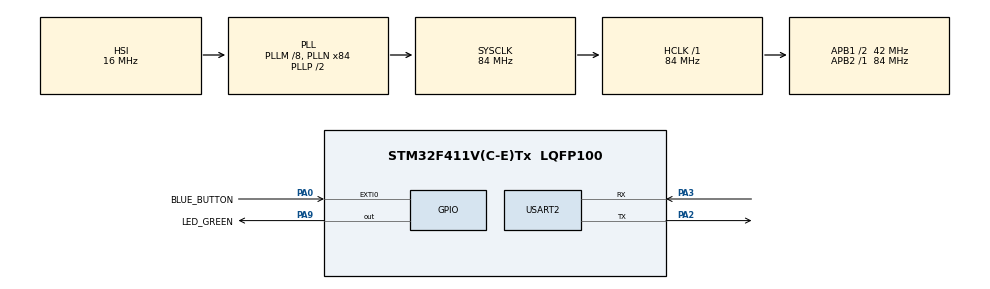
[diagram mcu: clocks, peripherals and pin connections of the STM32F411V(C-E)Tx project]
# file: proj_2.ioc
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FREERTOS.Queues01=adcQueue01,16,uint16_t,0,Dynamic,NULL,NULL
FREERTOS.Tasks01=ConsumerTask,24,256,StartConsumerTask,Default,NULL,Dynamic,NULL,NULL;ProducerTask,8,256,StartProducerTask,Default,NULL,Dynamic,NULL,NULL
FREERTOS.configUSE_NEWLIB_REENTRANT=1
Mcu.Family=STM32F4
Mcu.Name=STM32F411V(C-E)Tx
Mcu.Package=LQFP100
NVIC.EXTI0_IRQn=true\:5\:0\:false\:false\:true\:true\:true\:true\:true
NVIC.PriorityGroup=NVIC_PRIORITYGROUP_4
NVIC.TIM5_IRQn=true\:15\:0\:false\:false\:true\:false\:false\:true\:true
NVIC.TimeBase=TIM5_IRQn
NVIC.TimeBaseIP=TIM5
PA0-WKUP.GPIO_Label=BLUE_BUTTON
PA0-WKUP.Signal=GPXTI0
PA13.Mode=Trace_Asynchronous_SW
PA13.Signal=SYS_JTMS-SWDIO
PA14.Mode=Trace_Asynchronous_SW
PA14.Signal=SYS_JTCK-SWCLK
PA2.Mode=Asynchronous
PA2.Signal=USART2_TX
PA3.Mode=Asynchronous
PA3.Signal=USART2_RX
PA9.GPIO_Label=LED_GREEN
PA9.Signal=GPIO_Output
PB3.Mode=Trace_Asynchronous_SW
PB3.Signal=SYS_JTDO-SWO
ProjectManager.HeapSize=0x200
ProjectManager.StackSize=0x400
ProjectManager.TargetToolchain=STM32CubeIDE
RCC.48MHZClocksFreq_Value=42000000
RCC.AHBFreq_Value=84000000
RCC.APB1CLKDivider=RCC_HCLK_DIV2
RCC.APB1Freq_Value=42000000
RCC.APB1TimFreq_Value=84000000
RCC.APB2Freq_Value=84000000
RCC.APB2TimFreq_Value=84000000
RCC.CortexFreq_Value=84000000
RCC.HCLKFreq_Value=84000000
RCC.HSE_VALUE=25000000
RCC.HSI_VALUE=16000000
RCC.LSE_VALUE=32768
RCC.PLLM=8
RCC.PLLN=84
RCC.SYSCLKFreq_VALUE=84000000
RCC.SYSCLKSource=RCC_SYSCLKSOURCE_PLLCLK
RCC.VCOOutputFreq_Value=168000000
USART2.VirtualMode=VM_ASYNC
VP_FREERTOS_VS_CMSIS_V2.Mode=CMSIS_V2
VP_SYS_VS_tim5.Mode=TIM5
board=custom

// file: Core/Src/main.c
/* USER CODE BEGIN Header */
/**
  ******************************************************************************
  * @file           : main.c
  * @brief          : Main program body
  ******************************************************************************
  * @attention
  *
  * Copyright (c) 2025 STMicroelectronics.
  * All rights reserved.
  *
  * This software is licensed under terms that can be found in the LICENSE file
  * in the root directory of this software component.
  * If no LICENSE file comes with this software, it is provided AS-IS.
  *
  ******************************************************************************
  */
/* USER CODE END Header */
#include "main.h"
#include "cmsis_os.h"

/* USER CODE BEGIN Includes */
#include <stdio.h>
/* USER CODE END Includes */

UART_HandleTypeDef huart2;

/* Definitions for ConsumerTask */
osThreadId_t ConsumerTaskHandle;
const osThreadAttr_t ConsumerTask_attributes = {
  .name = "ConsumerTask",
  .stack_size = 256 * 4,
  .priority = (osPriority_t) osPriorityNormal,
};
/* Definitions for ProducerTask */
osThreadId_t ProducerTaskHandle;
const osThreadAttr_t ProducerTask_attributes = {
  .name = "ProducerTask",
  .stack_size = 256 * 4,
  .priority = (osPriority_t) osPriorityLow,
};
/* Definitions for adcQueue01 */
osMessageQueueId_t adcQueue01Handle;
const osMessageQueueAttr_t adcQueue01_attributes = {
  .name = "adcQueue01"
};

void SystemClock_Config(void);
static void MX_GPIO_Init(void);
static void MX_USART2_UART_Init(void);
void StartConsumerTask(void *argument);
void StartProducerTask(void *argument);

/* USER CODE BEGIN 0 */
int __io_putchar(int chr)
{
	ITM_SendChar(chr);
	return 1;
}
/* USER CODE END 0 */

int main(void)
{

  /* MCU Configuration--------------------------------------------------------*/

  /* Reset of all peripherals, Initializes the Flash interface and the Systick. */
  HAL_Init();

  /* Configure the system clock */
  SystemClock_Config();

  /* Initialize all configured peripherals */
  MX_GPIO_Init();
  MX_USART2_UART_Init();

  /* Init scheduler */
  osKernelInitialize();

  /* Create the queue(s) */
  /* creation of adcQueue01 */
  adcQueue01Handle = osMessageQueueNew (16, sizeof(uint16_t), &adcQueue01_attributes);

  /* Create the thread(s) */
  /* creation of ConsumerTask */
  ConsumerTaskHandle = osThreadNew(StartConsumerTask, NULL, &ConsumerTask_attributes);

  /* creation of ProducerTask */
  ProducerTaskHandle = osThreadNew(StartProducerTask, NULL, &ProducerTask_attributes);

  /* Start scheduler */
  printf("osKernelStart()\n");
  osKernelStart();

  /* We should never get here as control is now taken by the scheduler */

  /* Infinite loop */
  while (1)
  {

  }
}

void SystemClock_Config(void)
{
  RCC_OscInitTypeDef RCC_OscInitStruct = {0};
  RCC_ClkInitTypeDef RCC_ClkInitStruct = {0};

  /** Configure the main internal regulator output voltage
  */
  __HAL_RCC_PWR_CLK_ENABLE();
  __HAL_PWR_VOLTAGESCALING_CONFIG(PWR_REGULATOR_VOLTAGE_SCALE1);

  /** Initializes the RCC Oscillators according to the specified parameters
  * in the RCC_OscInitTypeDef structure.
  */
  RCC_OscInitStruct.OscillatorType = RCC_OSCILLATORTYPE_HSI;
  RCC_OscInitStruct.HSIState = RCC_HSI_ON;
  RCC_OscInitStruct.HSICalibrationValue = RCC_HSICALIBRATION_DEFAULT;
  RCC_OscInitStruct.PLL.PLLState = RCC_PLL_ON;
  RCC_OscInitStruct.PLL.PLLSource = RCC_PLLSOURCE_HSI;
  RCC_OscInitStruct.PLL.PLLM = 8;
  RCC_OscInitStruct.PLL.PLLN = 84;
  RCC_OscInitStruct.PLL.PLLP = RCC_PLLP_DIV2;
  RCC_OscInitStruct.PLL.PLLQ = 4;
  if (HAL_RCC_OscConfig(&RCC_OscInitStruct) != HAL_OK)
  {
    Error_Handler();
  }

  /** Initializes the CPU, AHB and APB buses clocks
  */
  RCC_ClkInitStruct.ClockType = RCC_CLOCKTYPE_HCLK|RCC_CLOCKTYPE_SYSCLK
                              |RCC_CLOCKTYPE_PCLK1|RCC_CLOCKTYPE_PCLK2;
  RCC_ClkInitStruct.SYSCLKSource = RCC_SYSCLKSOURCE_PLLCLK;
  RCC_ClkInitStruct.AHBCLKDivider = RCC_SYSCLK_DIV1;
  RCC_ClkInitStruct.APB1CLKDivider = RCC_HCLK_DIV2;
  RCC_ClkInitStruct.APB2CLKDivider = RCC_HCLK_DIV1;

  if (HAL_RCC_ClockConfig(&RCC_ClkInitStruct, FLASH_LATENCY_2) != HAL_OK)
  {
    Error_Handler();
  }
}

static void MX_USART2_UART_Init(void)
{

  huart2.Instance = USART2;
  huart2.Init.BaudRate = 115200;
  huart2.Init.WordLength = UART_WORDLENGTH_8B;
  huart2.Init.StopBits = UART_STOPBITS_1;
  huart2.Init.Parity = UART_PARITY_NONE;
  huart2.Init.Mode = UART_MODE_TX_RX;
  huart2.Init.HwFlowCtl = UART_HWCONTROL_NONE;
  huart2.Init.OverSampling = UART_OVERSAMPLING_16;
  if (HAL_UART_Init(&huart2) != HAL_OK)
  {
    Error_Handler();
  }

}

static void MX_GPIO_Init(void)
{
  GPIO_InitTypeDef GPIO_InitStruct = {0};

  /* GPIO Ports Clock Enable */
  __HAL_RCC_GPIOA_CLK_ENABLE();
  __HAL_RCC_GPIOB_CLK_ENABLE();

  /*Configure GPIO pin Output Level */
  HAL_GPIO_WritePin(LED_GREEN_GPIO_Port, LED_GREEN_Pin, GPIO_PIN_RESET);

  /*Configure GPIO pin : BLUE_BUTTON_Pin */
  GPIO_InitStruct.Pin = BLUE_BUTTON_Pin;
  GPIO_InitStruct.Mode = GPIO_MODE_IT_RISING;
  GPIO_InitStruct.Pull = GPIO_NOPULL;
  HAL_GPIO_Init(BLUE_BUTTON_GPIO_Port, &GPIO_InitStruct);

  /*Configure GPIO pin : LED_GREEN_Pin */
  GPIO_InitStruct.Pin = LED_GREEN_Pin;
  GPIO_InitStruct.Mode = GPIO_MODE_OUTPUT_PP;
  GPIO_InitStruct.Pull = GPIO_NOPULL;
  GPIO_InitStruct.Speed = GPIO_SPEED_FREQ_LOW;
  HAL_GPIO_Init(LED_GREEN_GPIO_Port, &GPIO_InitStruct);

  /* EXTI interrupt init*/
  HAL_NVIC_SetPriority(EXTI0_IRQn, 5, 0);
  HAL_NVIC_EnableIRQ(EXTI0_IRQn);

}

void StartConsumerTask(void *argument)
{
  /* USER CODE BEGIN 5 */
  /* Infinite loop */
  for(;;)
  {
	printf("ConsumerTask Start\r\n");
    osDelay(1000);
  }
  /* USER CODE END 5 */
}

void StartProducerTask(void *argument)
{
  /* USER CODE BEGIN StartProducerTask */
  /* Infinite loop */
  for(;;)
  {
	printf("ProcuderTask Start\r\n");
    osDelay(1000);
  }
  /* USER CODE END StartProducerTask */
}

void HAL_TIM_PeriodElapsedCallback(TIM_HandleTypeDef *htim)
{
  if (htim->Instance == TIM5)
  {
    HAL_IncTick();
  }
}

void Error_Handler(void)
{
  __disable_irq();
  while (1)
  {
  }
}
